# System_Clock_1 register map
Vendor: Texas Instruments
Peripheral module from a debugger description file (folder msp430).
Registers are 8-bit, read-write, reset 0x0 unless marked. A register's access mark holds for its fields unless they carry their own. Offsets are as the file gives them; lines under a group give offsets from that group; [hi:lo] are bit positions; {n}, {i} and the like mark numbered series; 'fields as' and 'values as' point back to an identical list; <NAME> marks a mode.

## System_Clock
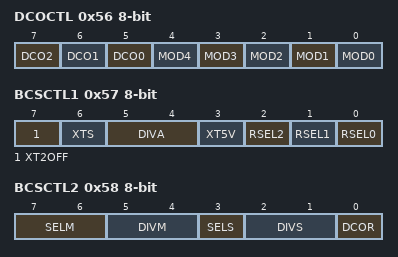
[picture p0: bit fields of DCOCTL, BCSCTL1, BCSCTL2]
0x56 DCOCTL — DCO Clock Frequency Control
  [7] DCO2 — DCO Select Bit 2
  [6] DCO1 — DCO Select Bit 1
  [5] DCO0 — DCO Select Bit 0
  [n] MOD{n} (n=0..4) — Modulation Bit {n}
0x57 BCSCTL1 — Basic Clock System Control 1
  [7] XT2OFF — Enable XT2CLK
  [6] XTS — LFXTCLK 0:Low Freq. / 1: High Freq.
  [5:4] DIVA — ACLK Divider 0
    0=ACLK Divider 0: /1; 1=ACLK Divider 1: /2; 2=ACLK Divider 2: /4; 3=ACLK Divider 3: /8
  [3] XT5V — XT5V should always be reset
  [2] RSEL2 — Range Select Bit 2
  [1] RSEL1 — Range Select Bit 1
  [0] RSEL0 — Range Select Bit 0
0x58 BCSCTL2 — Basic Clock System Control 2
  [7:6] SELM — MCLK Source Select 0
    0=MCLK Source Select 0: DCOCLK; 1=MCLK Source Select 1: DCOCLK; 2=MCLK Source Select 2: XT2CLK/LFXTCLK; 3=MCLK Source Select 3: LFXTCLK
  [5:4] DIVM — MCLK Divider 0
    0=MCLK Divider 0: /1; 1=MCLK Divider 1: /2; 2=MCLK Divider 2: /4; 3=MCLK Divider 3: /8
  [3] SELS — SMCLK Source Select 0:DCOCLK / 1:XT2CLK/LFXTCLK
  [2:1] DIVS — SMCLK Divider 0
    0=SMCLK Divider 0: /1; 1=SMCLK Divider 1: /2; 2=SMCLK Divider 2: /4; 3=SMCLK Divider 3: /8
  [0] DCOR — Enable External Resistor : 1
